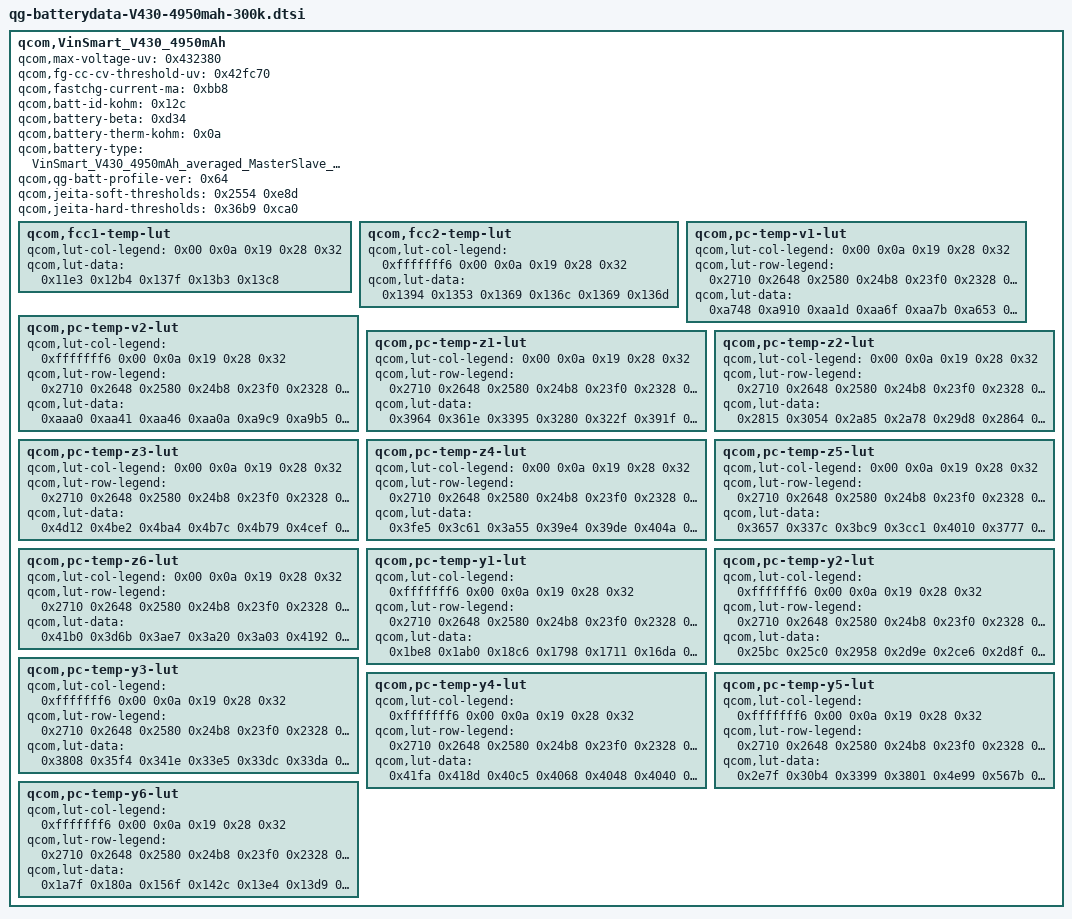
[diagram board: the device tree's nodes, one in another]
qcom,VinSmart_V430_4950mAh {
	qcom,max-voltage-uv = <0x432380>;
	qcom,fg-cc-cv-threshold-uv = <0x42fc70>;
	qcom,fastchg-current-ma = <0xbb8>;
	qcom,batt-id-kohm = <0x12c>;
	qcom,battery-beta = <0xd34>;
	qcom,battery-therm-kohm = <0x0a>;
	qcom,battery-type = "VinSmart_V430_4950mAh_averaged_MasterSlave_Nov11th2019";
	qcom,qg-batt-profile-ver = <0x64>;
	qcom,jeita-soft-thresholds = <0x2554 0xe8d>;
	qcom,jeita-hard-thresholds = <0x36b9 0xca0>;

	qcom,fcc1-temp-lut {
		qcom,lut-col-legend = <0x00 0x0a 0x19 0x28 0x32>;
		qcom,lut-data = <0x11e3 0x12b4 0x137f 0x13b3 0x13c8>;
	};

	qcom,fcc2-temp-lut {
		qcom,lut-col-legend = <0xfffffff6 0x00 0x0a 0x19 0x28 0x32>;
		qcom,lut-data = <0x1394 0x1353 0x1369 0x136c 0x1369 0x136d>;
	};

	qcom,pc-temp-v1-lut {
		qcom,lut-col-legend = <0x00 0x0a 0x19 0x28 0x32>;
		qcom,lut-row-legend = <0x2710 0x2648 0x2580 0x24b8 0x23f0 0x2328 0x2260 0x2198 0x20d0 0x2008 0x1f40 0x1e78 0x1db0 0x1ce8 0x1c20 0x1b58 0x1a90 0x19c8 0x1900 0x1838 0x1770 0x16a8 0x15e0 0x1518 0x1450 0x1388 0x12c0 0x11f8 0x1130 0x1068 0xfa0 0xed8 0xe10 0xd48 0xc80 0xbb8 0xaf0 0xa28 0x960 0x898 0x7d0 0x708 0x640 0x578 0x4b0 0x3e8 0x384 0x320 0x2bc 0x258 0x1f4 0x190 0x12c 0xc8 0x64 0x00>;
		qcom,lut-data = <0xa748 0xa910 0xaa1d 0xaa6f 0xaa7b 0xa653 0xa7fa 0xa968 0xa99a 0xa9a7 0xa56d 0xa70d 0xa86e 0xa8b7 0xa8cc 0xa492 0xa632 0xa771 0xa7ce 0xa7ea 0xa3bf 0xa556 0xa67f 0xa6e7 0xa707 0xa2f0 0xa47b 0xa590 0xa600 0xa621 0xa229 0xa3a6 0xa4b7 0xa51b 0xa53c 0xa171 0xa2d3 0xa3f3 0xa438 0xa459 0xa0d5 0xa206 0xa32c 0xa358 0xa379 0xa038 0xa149 0xa252 0xa27c 0xa29c 0x9f6a 0xa0a9 0xa178 0xa1a3 0xa1c0 0x9e50 0xa000 0xa0b3 0xa0cf 0xa0e9 0x9d45 0x9f1e 0xa001 0x9fff 0xa019 0x9c83 0x9e0a 0x9f42 0x9f36 0x9f50 0x9be3 0x9d20 0x9e5b 0x9e71 0x9e8b 0x9b5a 0x9c75 0x9d77 0x9db2 0x9dcc 0x9ae4 0x9be2 0x9cc1 0x9cff 0x9d15 0x9a78 0x9b59 0x9c26 0x9c59 0x9c6b 0x9a09 0x9adb 0x9b8e 0x9bb5 0x9bc5 0x9997 0x9a5d 0x9afc 0x9b12 0x9b1e 0x9927 0x99d8 0x9a5f 0x9a6c 0x9a76 0x98bf 0x9953 0x9993 0x99a4 0x99b8 0x9859 0x98d4 0x989f 0x98a1 0x98ca 0x97fb 0x9857 0x97db 0x97ce 0x97f8 0x97a4 0x97db 0x9744 0x9759 0x9776 0x9753 0x975c 0x96ce 0x9700 0x9712 0x9707 0x96df 0x967b 0x96a5 0x96ac 0x96c1 0x9678 0x963b 0x964b 0x9645 0x9680 0x9623 0x95fe 0x95f6 0x95e7 0x9644 0x95dc 0x95c2 0x95a5 0x9594 0x960e 0x95a6 0x958a 0x955a 0x954b 0x95db 0x9579 0x9556 0x951b 0x9507 0x95ab 0x9553 0x9526 0x94e6 0x94ca 0x957d 0x9531 0x94fa 0x94b1 0x948e 0x9551 0x9513 0x94d3 0x947d 0x9454 0x9528 0x94f1 0x94ab 0x944a 0x941b 0x94fd 0x94cd 0x9480 0x9417 0x93e0 0x94c9 0x94a2 0x9450 0x93e4 0x93a5 0x948a 0x9462 0x940e 0x93a2 0x935e 0x9440 0x940e 0x93b0 0x9345 0x9302 0x93e3 0x93ac 0x9342 0x92d8 0x9298 0x9371 0x9332 0x92ce 0x9266 0x9223 0x92f0 0x92a8 0x924b 0x91e5 0x91a0 0x9260 0x9206 0x91ad 0x914c 0x9109 0x91d3 0x9196 0x9124 0x90c7 0x9088 0x9176 0x913d 0x90d2 0x9074 0x9037 0x9151 0x911e 0x90b8 0x905f 0x9020 0x9133 0x9102 0x90a9 0x904c 0x900e 0x9111 0x90e4 0x9093 0x9036 0x8ffa 0x90bf 0x90a7 0x9058 0x8ff3 0x8fae 0x8fd0 0x8fb6 0x8f53 0x8ee0 0x8e8f 0x8e1d 0x8e02 0x8da9 0x8d31 0x8cde 0x8bf4 0x8bd2 0x8b7e 0x8aff 0x8aac 0x8910 0x88e6 0x8884 0x8804 0x87b2 0x8463 0x845a 0x83ef 0x836a 0x8327 0x7530 0x7530 0x7530 0x7530 0x7530>;
	};

	qcom,pc-temp-v2-lut {
		qcom,lut-col-legend = <0xfffffff6 0x00 0x0a 0x19 0x28 0x32>;
		qcom,lut-row-legend = <0x2710 0x2648 0x2580 0x24b8 0x23f0 0x2328 0x2260 0x2198 0x20d0 0x2008 0x1f40 0x1e78 0x1db0 0x1ce8 0x1c20 0x1b58 0x1a90 0x19c8 0x1900 0x1838 0x1770 0x16a8 0x15e0 0x1518 0x1450 0x1388 0x12c0 0x11f8 0x1130 0x1068 0xfa0 0xed8 0xe10 0xd48 0xc80 0xbb8 0xaf0 0xa28 0x960 0x898 0x7d0 0x708 0x640 0x578 0x4b0 0x3e8 0x384 0x320 0x2bc 0x258 0x1f4 0x190 0x12c 0xc8 0x64 0x00>;
		qcom,lut-data = <0xaaa0 0xaa41 0xaa46 0xaa0a 0xa9c9 0xa9b5 0xa921 0xa8d2 0xa8fd 0xa8e0 0xa8bc 0xa8b5 0xa7c2 0xa781 0xa7d0 0xa7cb 0xa7bb 0xa7be 0xa688 0xa655 0xa6c1 0xa6cc 0xa6c7 0xa6d0 0xa56d 0xa547 0xa5d0 0xa5e5 0xa5e3 0xa5ec 0xa465 0xa44a 0xa4e6 0xa503 0xa502 0xa50b 0xa36a 0xa357 0xa3fb 0xa41f 0xa41f 0xa429 0xa27f 0xa271 0xa315 0xa340 0xa341 0xa34a 0xa19f 0xa198 0xa230 0xa263 0xa265 0xa26e 0xa0c9 0xa0c7 0xa14b 0xa18a 0xa18c 0xa195 0xa006 0xa00f 0xa07d 0xa0b7 0xa0b8 0xa0c0 0x9f6d 0x9f86 0x9fdb 0x9ff3 0x9fe9 0x9ff0 0x9ecb 0x9f03 0x9f41 0x9f33 0x9f1f 0x9f24 0x9db5 0x9e22 0x9e6d 0x9e63 0x9e5c 0x9e61 0x9c13 0x9c99 0x9d4f 0x9d82 0x9d9e 0x9da5 0x9ad6 0x9b43 0x9c50 0x9cb9 0x9ce6 0x9cee 0x9a1a 0x9a80 0x9b9d 0x9c1d 0x9c3b 0x9c41 0x997c 0x99e3 0x9afd 0x9b8e 0x9b93 0x9b96 0x98d8 0x993c 0x9a46 0x9ae4 0x9ae9 0x9aec 0x9838 0x9890 0x997f 0x9a24 0x9a3b 0x9a41 0x97a2 0x97ed 0x98be 0x995b 0x9981 0x9989 0x9712 0x9751 0x9806 0x987f 0x98a0 0x98aa 0x9690 0x96c0 0x975b 0x97ad 0x97c3 0x97cf 0x9620 0x9642 0x96c5 0x9711 0x9724 0x972f 0x95bb 0x95d2 0x9640 0x9695 0x96a9 0x96b2 0x9563 0x9572 0x95ca 0x9625 0x963b 0x9643 0x9513 0x9523 0x9562 0x95bf 0x95d6 0x95dc 0x94cb 0x94df 0x9506 0x9561 0x957b 0x957e 0x9486 0x94a1 0x94bc 0x950c 0x9526 0x9527 0x9445 0x9469 0x947d 0x94bf 0x94d9 0x94d8 0x9407 0x9436 0x9446 0x9478 0x9492 0x9490 0x93ca 0x9405 0x9413 0x9435 0x9451 0x944f 0x9391 0x93d6 0x93e4 0x93f6 0x9413 0x9410 0x9359 0x93a5 0x93b6 0x93bb 0x93cf 0x93c9 0x9322 0x9375 0x938b 0x9386 0x9387 0x937a 0x92eb 0x9342 0x935e 0x934e 0x9338 0x9320 0x92b2 0x930b 0x932d 0x9312 0x92dd 0x92b7 0x9279 0x92d0 0x92f6 0x92d3 0x9280 0x924c 0x923d 0x928b 0x92b5 0x928e 0x922e 0x91f4 0x9201 0x923c 0x9268 0x9246 0x91e4 0x91a7 0x91c2 0x91e5 0x9212 0x91f5 0x9193 0x9155 0x9181 0x9186 0x91ad 0x9195 0x9134 0x90f8 0x9134 0x9125 0x913c 0x9124 0x90c8 0x908e 0x90db 0x90cc 0x90c0 0x90a3 0x904e 0x9013 0x907e 0x9079 0x904a 0x902a 0x8feb 0x8fb4 0x9006 0x9026 0x8ff8 0x8ff1 0x8fbf 0x8f8c 0x8fbd 0x8ff6 0x8fdc 0x8fdb 0x8fb2 0x8f81 0x8f5c 0x8fc0 0x8fbc 0x8fc6 0x8f9e 0x8f70 0x8eee 0x8f79 0x8f8a 0x8fa0 0x8f7e 0x8f4f 0x8e4f 0x8f0a 0x8f34 0x8f59 0x8f21 0x8ee9 0x8d54 0x8e2f 0x8e6b 0x8e65 0x8de7 0x8d9f 0x8beb 0x8cad 0x8cd5 0x8ca5 0x8c13 0x8bcb 0x89cf 0x8a72 0x8a97 0x8a4c 0x89ac 0x8967 0x86a1 0x873f 0x8776 0x8727 0x8669 0x8624 0x8141 0x8230 0x8296 0x825f 0x8187 0x8146 0x7397 0x75a4 0x7559 0x7359 0x7341 0x7466>;
	};

	qcom,pc-temp-z1-lut {
		qcom,lut-col-legend = <0x00 0x0a 0x19 0x28 0x32>;
		qcom,lut-row-legend = <0x2710 0x2648 0x2580 0x24b8 0x23f0 0x2328 0x2260 0x2198 0x20d0 0x2008 0x1f40 0x1e78 0x1db0 0x1ce8 0x1c20 0x1b58 0x1a90 0x19c8 0x1900 0x1838 0x1770 0x16a8 0x15e0 0x1518 0x1450 0x1388 0x12c0 0x11f8 0x1130 0x1068 0xfa0 0xed8 0xe10 0xd48 0xc80 0xbb8 0xaf0 0xa28 0x960 0x898 0x7d0 0x708 0x640 0x578 0x4b0 0x3e8 0x384 0x320 0x2bc 0x258 0x1f4 0x190 0x12c 0xc8 0x64 0x00>;
		qcom,lut-data = <0x3964 0x361e 0x3395 0x3280 0x322f 0x391f 0x3605 0x337d 0x3272 0x322a 0x3913 0x3605 0x337d 0x3269 0x3220 0x3923 0x3607 0x337b 0x3263 0x3218 0x392f 0x3604 0x336e 0x325d 0x3215 0x392a 0x35f8 0x3362 0x3257 0x3215 0x3916 0x35ef 0x3363 0x3255 0x3214 0x3904 0x35ea 0x3369 0x3255 0x3217 0x38f6 0x35e4 0x336b 0x3255 0x321b 0x38e6 0x35e3 0x336a 0x3257 0x3220 0x38d4 0x35eb 0x3369 0x325b 0x3226 0x38b9 0x35f2 0x3369 0x325e 0x3229 0x38a0 0x35e9 0x3368 0x325f 0x322a 0x388d 0x35d1 0x3367 0x3260 0x322b 0x387d 0x35c6 0x3362 0x3260 0x322c 0x3876 0x35cc 0x335e 0x3260 0x322e 0x3879 0x35d7 0x335f 0x3262 0x3230 0x387d 0x35de 0x3365 0x3263 0x3232 0x387a 0x35e5 0x336b 0x3265 0x3233 0x386e 0x35ec 0x3375 0x3267 0x3235 0x3864 0x35f5 0x337c 0x326b 0x3238 0x3865 0x35ff 0x337c 0x326e 0x323a 0x386b 0x3606 0x337a 0x3271 0x323d 0x386d 0x360e 0x337a 0x3275 0x3240 0x386f 0x3613 0x337d 0x3279 0x3244 0x3872 0x3614 0x3382 0x327c 0x3249 0x3870 0x3614 0x338a 0x3280 0x324d 0x385e 0x3616 0x3394 0x3286 0x3250 0x384b 0x361f 0x3398 0x328b 0x3254 0x384e 0x3626 0x3398 0x328e 0x3258 0x3864 0x3628 0x3399 0x3292 0x325e 0x3873 0x3629 0x339f 0x3297 0x3262 0x386e 0x362b 0x33a8 0x329d 0x3267 0x3862 0x3630 0x33ad 0x32a3 0x326b 0x3863 0x3638 0x33ae 0x32a7 0x3270 0x387f 0x3640 0x33b0 0x32aa 0x3274 0x389f 0x364c 0x33b3 0x32af 0x3277 0x38a9 0x3657 0x33b8 0x32b6 0x327c 0x38ad 0x3663 0x33bf 0x32bb 0x3280 0x38b0 0x3671 0x33cd 0x32c0 0x3285 0x38b7 0x3675 0x33d8 0x32c5 0x328a 0x38bf 0x3677 0x33da 0x32c8 0x328e 0x38b6 0x3679 0x33dc 0x32cb 0x3292 0x389c 0x366f 0x33de 0x32d2 0x3298 0x3896 0x367b 0x33dd 0x32d9 0x329c 0x38a7 0x3674 0x33e3 0x32da 0x329d 0x38ab 0x3669 0x33e4 0x32dd 0x32a0 0x38af 0x366b 0x33e3 0x32dd 0x32a1 0x38b1 0x367a 0x33e3 0x32e5 0x32a5 0x38a0 0x367a 0x33e3 0x32e5 0x32a9 0x38ab 0x36a3 0x33f4 0x32ec 0x32af 0x38c5 0x369a 0x33fa 0x32f9 0x32b9 0x38c2 0x36b3 0x3409 0x3305 0x32c5 0x38e8 0x36cb 0x3427 0x331e 0x32d6 0x38e8 0x36cb 0x3427 0x331e 0x32d6 0x38e8 0x36cb 0x3427 0x331e 0x32d6>;
	};

	qcom,pc-temp-z2-lut {
		qcom,lut-col-legend = <0x00 0x0a 0x19 0x28 0x32>;
		qcom,lut-row-legend = <0x2710 0x2648 0x2580 0x24b8 0x23f0 0x2328 0x2260 0x2198 0x20d0 0x2008 0x1f40 0x1e78 0x1db0 0x1ce8 0x1c20 0x1b58 0x1a90 0x19c8 0x1900 0x1838 0x1770 0x16a8 0x15e0 0x1518 0x1450 0x1388 0x12c0 0x11f8 0x1130 0x1068 0xfa0 0xed8 0xe10 0xd48 0xc80 0xbb8 0xaf0 0xa28 0x960 0x898 0x7d0 0x708 0x640 0x578 0x4b0 0x3e8 0x384 0x320 0x2bc 0x258 0x1f4 0x190 0x12c 0xc8 0x64 0x00>;
		qcom,lut-data = <0x2815 0x3054 0x2a85 0x2a78 0x29d8 0x2864 0x296f 0x514d 0x2a4b 0x29ce 0x2865 0x2962 0x3c2a 0x2a8d 0x29f7 0x284d 0x2953 0x31d8 0x2ac6 0x2a39 0x283b 0x2948 0x2f08 0x2aca 0x2a4d 0x283a 0x2940 0x2d04 0x2ac1 0x2a7e 0x283d 0x293b 0x2c62 0x2ab4 0x2aab 0x283d 0x293c 0x2c6a 0x2a96 0x2a8d 0x2836 0x293f 0x2c85 0x2a74 0x2a4e 0x282d 0x2943 0x2c9a 0x2a60 0x2a3a 0x2828 0x2955 0x2cad 0x2a50 0x2a44 0x2824 0x2968 0x2c8d 0x2a42 0x2a45 0x281e 0x2956 0x2c49 0x2a30 0x29ec 0x2813 0x2917 0x2c33 0x2a22 0x2979 0x2800 0x28f5 0x2cf2 0x2a2b 0x296f 0x27ec 0x28fb 0x2dd2 0x2a44 0x2990 0x27d7 0x2906 0x2d44 0x2a45 0x29ab 0x27c3 0x2912 0x2b4f 0x2a13 0x29b7 0x27b2 0x2923 0x2a6f 0x29ec 0x29c2 0x27a5 0x292d 0x2a7b 0x2a17 0x29cf 0x2799 0x292d 0x2a88 0x2a68 0x29de 0x278a 0x292b 0x2a82 0x2a7c 0x29e5 0x2776 0x292e 0x2a68 0x2a7a 0x29e7 0x2766 0x2934 0x2a58 0x2a76 0x29e9 0x275b 0x293d 0x2a57 0x2a41 0x29f9 0x2753 0x294f 0x2a5f 0x29ef 0x2a1a 0x274b 0x296d 0x2a6f 0x2a02 0x2a52 0x2709 0x2983 0x2a87 0x2aa5 0x2ac9 0x26b3 0x2990 0x2a9a 0x2b07 0x2b0f 0x2672 0x299b 0x2aaf 0x2aef 0x2aad 0x2600 0x29a8 0x2abc 0x2abc 0x2a00 0x25b1 0x29b7 0x2abe 0x2a83 0x29b3 0x25a6 0x29c4 0x2abf 0x2a3b 0x2988 0x25a2 0x29cd 0x2abf 0x2a1e 0x297c 0x2592 0x29d6 0x2abe 0x2a4b 0x2992 0x254a 0x29e6 0x2abd 0x2a92 0x29b1 0x24fd 0x2a03 0x2ac3 0x2abd 0x29ce 0x24e9 0x2a1d 0x2ad1 0x2ae0 0x29f9 0x24da 0x2a2c 0x2ae7 0x2b06 0x2a20 0x24d1 0x2a36 0x2b13 0x2b3c 0x2a41 0x24de 0x2a3e 0x2b31 0x2b64 0x2a5a 0x24fb 0x2a44 0x2b2c 0x2b77 0x2a68 0x2535 0x2a4d 0x2b24 0x2b84 0x2a75 0x257a 0x2a60 0x2b2b 0x2b6d 0x2a91 0x258c 0x2915 0x2b51 0x2b3b 0x2a9b 0x25ed 0x2ae7 0x2b65 0x2adb 0x2a88 0x25e8 0x2e5c 0x2b62 0x2adb 0x2a86 0x25b6 0x30da 0x2ba6 0x2ad9 0x2a67 0x25cb 0x397d 0x2bc7 0x2af4 0x2ae6 0x25ce 0x4dff 0x2beb 0x2b68 0x2b80 0x25b5 0x366e 0x2be2 0x2b55 0x2a5a 0x257c 0x3273 0x2ba1 0x2ab4 0x29b2 0x2516 0x29b4 0x2bb2 0x2a71 0x2988 0x24d0 0x2771 0x2b69 0x2a3a 0x294a 0x24d0 0x2771 0x2b69 0x2a3a 0x294a 0x24d0 0x2771 0x2b69 0x2a3a 0x294a>;
	};

	qcom,pc-temp-z3-lut {
		qcom,lut-col-legend = <0x00 0x0a 0x19 0x28 0x32>;
		qcom,lut-row-legend = <0x2710 0x2648 0x2580 0x24b8 0x23f0 0x2328 0x2260 0x2198 0x20d0 0x2008 0x1f40 0x1e78 0x1db0 0x1ce8 0x1c20 0x1b58 0x1a90 0x19c8 0x1900 0x1838 0x1770 0x16a8 0x15e0 0x1518 0x1450 0x1388 0x12c0 0x11f8 0x1130 0x1068 0xfa0 0xed8 0xe10 0xd48 0xc80 0xbb8 0xaf0 0xa28 0x960 0x898 0x7d0 0x708 0x640 0x578 0x4b0 0x3e8 0x384 0x320 0x2bc 0x258 0x1f4 0x190 0x12c 0xc8 0x64 0x00>;
		qcom,lut-data = <0x4d12 0x4be2 0x4ba4 0x4b7c 0x4b79 0x4cef 0x4c85 0x4b72 0x4b95 0x4b88 0x4ce3 0x4c94 0x4ba9 0x4ba2 0x4b92 0x4cdd 0x4c99 0x4bd5 0x4bad 0x4b98 0x4cdc 0x4c98 0x4be8 0x4bb4 0x4b9e 0x4cdf 0x4c92 0x4bf6 0x4bb9 0x4ba4 0x4ce7 0x4c8c 0x4c03 0x4bbb 0x4ba9 0x4cee 0x4c88 0x4c12 0x4bbb 0x4ba9 0x4cf4 0x4c85 0x4c19 0x4bba 0x4ba9 0x4cfa 0x4c80 0x4c14 0x4bb9 0x4ba9 0x4cff 0x4c7b 0x4c0b 0x4bb4 0x4ba7 0x4d05 0x4c7a 0x4c02 0x4bb0 0x4ba4 0x4d08 0x4c7a 0x4bf9 0x4bac 0x4b9e 0x4d02 0x4c78 0x4bf4 0x4ba9 0x4b97 0x4cf1 0x4c72 0x4bf3 0x4ba7 0x4b94 0x4ce0 0x4c5f 0x4bf1 0x4ba6 0x4b93 0x4cd3 0x4c44 0x4be9 0x4ba2 0x4b91 0x4cc5 0x4c31 0x4bd6 0x4b9b 0x4b8c 0x4cb6 0x4c21 0x4bcd 0x4b96 0x4b88 0x4ca6 0x4c1a 0x4bcc 0x4b97 0x4b88 0x4c95 0x4c20 0x4bcb 0x4b9a 0x4b88 0x4c86 0x4c28 0x4bcf 0x4b9c 0x4b87 0x4c76 0x4c2a 0x4bdb 0x4b9c 0x4b85 0x4c66 0x4c32 0x4be0 0x4b9d 0x4b83 0x4c53 0x4c3c 0x4bdd 0x4b97 0x4b7f 0x4c3f 0x4c45 0x4bda 0x4b8d 0x4b7b 0x4c2c 0x4c51 0x4bd7 0x4b8d 0x4b7f 0x4c1a 0x4c55 0x4bd4 0x4b94 0x4b9d 0x4c08 0x4c52 0x4bd3 0x4b9e 0x4bb2 0x4bf6 0x4c4e 0x4bd4 0x4bab 0x4baf 0x4be3 0x4c49 0x4bd5 0x4bb6 0x4ba8 0x4bd2 0x4c41 0x4bd6 0x4bb6 0x4ba3 0x4bc6 0x4c39 0x4bd8 0x4baf 0x4b9d 0x4bbb 0x4c30 0x4bd9 0x4ba9 0x4b98 0x4baf 0x4c26 0x4bd6 0x4ba6 0x4b93 0x4b9a 0x4c1d 0x4bd4 0x4ba2 0x4b8e 0x4b84 0x4c14 0x4bd1 0x4b9e 0x4b8a 0x4b76 0x4c0f 0x4bcf 0x4b9a 0x4b87 0x4b5e 0x4c0f 0x4bcd 0x4b98 0x4b85 0x4b4c 0x4c0e 0x4bcc 0x4b97 0x4b84 0x4b4a 0x4c0d 0x4bcb 0x4b97 0x4b83 0x4b49 0x4c08 0x4bc8 0x4b95 0x4b84 0x4b46 0x4c05 0x4bc5 0x4b94 0x4b86 0x4b44 0x4c08 0x4bc4 0x4b94 0x4b88 0x4b43 0x4b6f 0x4bbe 0x4b90 0x4b86 0x4b41 0x4b3c 0x4bb2 0x4b89 0x4b80 0x4b41 0x4b3b 0x4bad 0x4b82 0x4b7c 0x4b42 0x4b3a 0x4b8b 0x4b81 0x4b77 0x4b41 0x4b39 0x4b85 0x4b7f 0x4b6d 0x4b41 0x4b38 0x4b83 0x4b78 0x4b67 0x4b42 0x4b39 0x4b9a 0x4b7e 0x4b80 0x4b43 0x4b3a 0x4b99 0x4b85 0x4b88 0x4b45 0x4b3c 0x4b74 0x4b85 0x4b89 0x4b47 0x4b3f 0x4b75 0x4b83 0x4b87 0x4b47 0x4b3f 0x4b75 0x4b83 0x4b87 0x4b47 0x4b3f 0x4b75 0x4b83 0x4b87>;
	};

	qcom,pc-temp-z4-lut {
		qcom,lut-col-legend = <0x00 0x0a 0x19 0x28 0x32>;
		qcom,lut-row-legend = <0x2710 0x2648 0x2580 0x24b8 0x23f0 0x2328 0x2260 0x2198 0x20d0 0x2008 0x1f40 0x1e78 0x1db0 0x1ce8 0x1c20 0x1b58 0x1a90 0x19c8 0x1900 0x1838 0x1770 0x16a8 0x15e0 0x1518 0x1450 0x1388 0x12c0 0x11f8 0x1130 0x1068 0xfa0 0xed8 0xe10 0xd48 0xc80 0xbb8 0xaf0 0xa28 0x960 0x898 0x7d0 0x708 0x640 0x578 0x4b0 0x3e8 0x384 0x320 0x2bc 0x258 0x1f4 0x190 0x12c 0xc8 0x64 0x00>;
		qcom,lut-data = <0x3fe5 0x3c61 0x3a55 0x39e4 0x39de 0x404a 0x3cd2 0x3adc 0x3a26 0x39eb 0x4017 0x3c78 0x3aa0 0x3a21 0x39f9 0x3f55 0x3bdf 0x3a61 0x3a08 0x39ea 0x3e85 0x3b76 0x3a32 0x39f0 0x39da 0x3df4 0x3b2b 0x3a09 0x39d6 0x39c6 0x3d74 0x3aec 0x39df 0x39c0 0x39b3 0x3d01 0x3ab7 0x39ac 0x39ac 0x39a3 0x3c94 0x3a8b 0x3989 0x399b 0x3995 0x3c35 0x3a61 0x397c 0x398c 0x3986 0x3bf4 0x3a2f 0x3973 0x397e 0x3978 0x3bc7 0x3a04 0x3966 0x3973 0x396e 0x3b9e 0x39f5 0x3955 0x396b 0x396a 0x3b70 0x39eb 0x394c 0x3964 0x3966 0x3b40 0x39e2 0x394b 0x395c 0x3961 0x3b18 0x39d8 0x394b 0x3956 0x395a 0x3af8 0x39ce 0x394f 0x3951 0x3953 0x3adf 0x39c9 0x3955 0x394b 0x394c 0x3ad4 0x39c6 0x3957 0x3948 0x3947 0x3ace 0x39c1 0x3953 0x3948 0x3948 0x3acb 0x39b3 0x3950 0x394a 0x394e 0x3acb 0x39a1 0x3967 0x3959 0x395c 0x3acc 0x3998 0x39a8 0x39ad 0x39a3 0x3acd 0x398f 0x39d1 0x39e7 0x39dc 0x3acf 0x3988 0x39e4 0x39e4 0x39da 0x3ad3 0x398a 0x39ed 0x39da 0x39cf 0x3ad8 0x3990 0x39e6 0x39cc 0x39bc 0x3adf 0x3995 0x39ce 0x39b3 0x3990 0x3ae6 0x3997 0x39b8 0x3999 0x396d 0x3aec 0x3999 0x39a6 0x397f 0x3962 0x3af3 0x3997 0x3995 0x396a 0x395b 0x3af7 0x3991 0x3986 0x395e 0x3955 0x3af6 0x398b 0x3979 0x3957 0x394e 0x3af3 0x3987 0x396e 0x3954 0x394b 0x3af1 0x3983 0x3966 0x3953 0x394c 0x3af3 0x3980 0x3960 0x3953 0x394d 0x3af4 0x397e 0x395e 0x3953 0x394e 0x3af3 0x397c 0x395d 0x3953 0x3951 0x3af0 0x3978 0x395d 0x3954 0x3954 0x3aeb 0x3975 0x3965 0x395d 0x395c 0x3ae4 0x3974 0x396b 0x3965 0x3962 0x3ad9 0x3978 0x3967 0x3962 0x3960 0x3acc 0x3979 0x3962 0x395c 0x395a 0x3ab7 0x396f 0x3962 0x395f 0x395c 0x3a6a 0x39e9 0x395a 0x395c 0x395a 0x3a60 0x3a0d 0x3947 0x394a 0x3948 0x3a5e 0x3a05 0x3942 0x3944 0x3941 0x3a59 0x3a00 0x3959 0x3936 0x3934 0x3a53 0x39fb 0x3956 0x3929 0x392b 0x3a4f 0x39f8 0x3955 0x3931 0x3932 0x3a54 0x3a02 0x3951 0x3948 0x393a 0x3a6f 0x3a13 0x395b 0x3948 0x393b 0x3a84 0x3a20 0x3987 0x394b 0x393e 0x3a9d 0x3a2f 0x398c 0x3951 0x3943 0x3a9d 0x3a2f 0x398c 0x3951 0x3943 0x3a9d 0x3a2f 0x398c 0x3951 0x3943>;
	};

	qcom,pc-temp-z5-lut {
		qcom,lut-col-legend = <0x00 0x0a 0x19 0x28 0x32>;
		qcom,lut-row-legend = <0x2710 0x2648 0x2580 0x24b8 0x23f0 0x2328 0x2260 0x2198 0x20d0 0x2008 0x1f40 0x1e78 0x1db0 0x1ce8 0x1c20 0x1b58 0x1a90 0x19c8 0x1900 0x1838 0x1770 0x16a8 0x15e0 0x1518 0x1450 0x1388 0x12c0 0x11f8 0x1130 0x1068 0xfa0 0xed8 0xe10 0xd48 0xc80 0xbb8 0xaf0 0xa28 0x960 0x898 0x7d0 0x708 0x640 0x578 0x4b0 0x3e8 0x384 0x320 0x2bc 0x258 0x1f4 0x190 0x12c 0xc8 0x64 0x00>;
		qcom,lut-data = <0x3657 0x337c 0x3bc9 0x3cc1 0x4010 0x3777 0x3ced 0x3314 0x42c7 0x45d7 0x392a 0x3e89 0x3838 0x463e 0x483f 0x3b91 0x3f53 0x3e0f 0x4a87 0x4ae6 0x3e03 0x3ffd 0x438d 0x4de8 0x4dea 0x4044 0x4082 0x49b1 0x50ce 0x51b5 0x427a 0x412c 0x4fea 0x5342 0x557e 0x449d 0x42a0 0x55f1 0x55c6 0x5801 0x46b7 0x4474 0x5ad5 0x5843 0x5a33 0x48d7 0x45b3 0x5eca 0x5a33 0x5da3 0x4b1f 0x46e7 0x62a3 0x5c1c 0x6315 0x4dbd 0x4882 0x671f 0x5d43 0x65c6 0x4f48 0x4c28 0x6c6a 0x5f76 0x637a 0x4f43 0x5222 0x71c4 0x6332 0x6066 0x4ee4 0x54c6 0x784b 0x68ae 0x6208 0x4e53 0x5157 0x7cc0 0x6f3a 0x69f2 0x4d14 0x4b9b 0x79b3 0x709a 0x6ec2 0x4b2d 0x487a 0x70af 0x6d24 0x6f69 0x4914 0x4600 0x6d2d 0x6a91 0x702b 0x467c 0x44fb 0x7182 0x75b5 0x7582 0x43d9 0x4954 0x7a51 0x8ada 0x8047 0x41ad 0x5109 0x9557 0x8fab 0x828e 0x3fb8 0x576b 0xc7be 0x89bd 0x7423 0x3dd4 0x6326 0xd861 0x8025 0x61a6 0x3bed 0x72c2 0xbdaf 0x6ab6 0x5284 0x3a1c 0x8c69 0x9c63 0x51c6 0x454c 0x387d 0xada7 0x88d0 0x4cbf 0x4526 0x3705 0xb840 0x794a 0x4d54 0x58cb 0x35a2 0xb598 0x73d6 0x4f84 0x69bd 0x3444 0xb0b0 0x72a8 0x5eb4 0x6db9 0x32e7 0xa8e5 0x7225 0x7389 0x7045 0x31c5 0x9bf0 0x760e 0x7b74 0x7445 0x30f8 0x8f97 0x813e 0x7f55 0x7b0e 0x304a 0x82b1 0x8a74 0x8449 0x8037 0x2f91 0x75a4 0x923e 0x8f16 0x8364 0x2e91 0x6dc5 0x9826 0x984b 0x859f 0x2db3 0x67f7 0x9b9d 0x9614 0x8490 0x2d53 0x652e 0x9e59 0x8da6 0x7f37 0x2cdd 0x6813 0x9e75 0x866f 0x786b 0x2c88 0x6dda 0x9b3e 0x7ecb 0x6d04 0x2c94 0x6f35 0x9638 0x76f8 0x640d 0x2cc1 0x69c2 0x8cad 0x708d 0x63b0 0x2ce1 0x6826 0x831f 0x6b67 0x6415 0x2d09 0x7395 0x8094 0x6841 0x64ef 0x2e61 0x3fde 0x80db 0x644d 0x635f 0x2e11 0x2f0d 0x7747 0x60e3 0x5d84 0x2de9 0x2ead 0x6e4f 0x583b 0x5859 0x2ded 0x2e85 0x467e 0x5e01 0x5b7f 0x2de9 0x2e7f 0x4377 0x66f8 0x5659 0x2df5 0x2e86 0x43ab 0x5724 0x4993 0x2e43 0x2ed4 0x5220 0x4ad8 0x5695 0x2e56 0x2e71 0x4a07 0x4b23 0x56da 0x2dce 0x2e64 0x37b4 0x481e 0x5255 0x2d4f 0x2db8 0x3677 0x42fb 0x49f2 0x2d4f 0x2db8 0x3677 0x42fb 0x49f2 0x2d4f 0x2db8 0x3677 0x42fb 0x49f2>;
	};

	qcom,pc-temp-z6-lut {
		qcom,lut-col-legend = <0x00 0x0a 0x19 0x28 0x32>;
		qcom,lut-row-legend = <0x2710 0x2648 0x2580 0x24b8 0x23f0 0x2328 0x2260 0x2198 0x20d0 0x2008 0x1f40 0x1e78 0x1db0 0x1ce8 0x1c20 0x1b58 0x1a90 0x19c8 0x1900 0x1838 0x1770 0x16a8 0x15e0 0x1518 0x1450 0x1388 0x12c0 0x11f8 0x1130 0x1068 0xfa0 0xed8 0xe10 0xd48 0xc80 0xbb8 0xaf0 0xa28 0x960 0x898 0x7d0 0x708 0x640 0x578 0x4b0 0x3e8 0x384 0x320 0x2bc 0x258 0x1f4 0x190 0x12c 0xc8 0x64 0x00>;
		qcom,lut-data = <0x41b0 0x3d6b 0x3ae7 0x3a20 0x3a03 0x4192 0x3dc5 0x3aff 0x3a45 0x3a0e 0x414d 0x3d8f 0x3af4 0x3a46 0x3a16 0x40cb 0x3d30 0x3ae8 0x3a3e 0x3a13 0x4052 0x3cea 0x3ad6 0x3a36 0x3a0f 0x3ffd 0x3cb2 0x3ac2 0x3a2c 0x3a0a 0x3fb4 0x3c83 0x3ab0 0x3a22 0x3a04 0x3f75 0x3c5d 0x3a9e 0x3a1a 0x39ff 0x3f3d 0x3c3d 0x3a8e 0x3a12 0x39f9 0x3f09 0x3c1f 0x3a83 0x3a0a 0x39f3 0x3ed9 0x3c02 0x3a79 0x3a02 0x39ed 0x3eac 0x3be7 0x3a6e 0x39fb 0x39e8 0x3e82 0x3bd4 0x3a60 0x39f5 0x39e2 0x3e58 0x3bc4 0x3a58 0x39f0 0x39dd 0x3e2f 0x3bb4 0x3a55 0x39ec 0x39d9 0x3e0f 0x3ba1 0x3a53 0x39e8 0x39d5 0x3df8 0x3b90 0x3a4e 0x39e4 0x39d2 0x3de5 0x3b89 0x3a48 0x39de 0x39cc 0x3dd5 0x3b86 0x3a45 0x39db 0x39c8 0x3dc8 0x3b84 0x3a45 0x39db 0x39c9 0x3dbd 0x3b83 0x3a45 0x39dd 0x39cb 0x3db3 0x3b82 0x3a52 0x39e7 0x39d2 0x3daa 0x3b83 0x3a75 0x3a0c 0x39ef 0x3da0 0x3b85 0x3a8a 0x3a25 0x3a08 0x3d95 0x3b8a 0x3a92 0x3a22 0x3a06 0x3d89 0x3b93 0x3a96 0x3a1a 0x3a00 0x3d80 0x3ba0 0x3a93 0x3a13 0x39fb 0x3d78 0x3ba6 0x3a88 0x3a0e 0x39f8 0x3d71 0x3ba7 0x3a80 0x3a0a 0x39f6 0x3d6c 0x3ba8 0x3a7a 0x3a07 0x39f1 0x3d66 0x3ba7 0x3a75 0x3a04 0x39eb 0x3d62 0x3ba3 0x3a72 0x3a00 0x39e6 0x3d61 0x3ba0 0x3a6f 0x39fa 0x39e1 0x3d61 0x3b9d 0x3a6d 0x39f6 0x39dd 0x3d61 0x3b9b 0x3a6a 0x39f5 0x39db 0x3d62 0x3b9a 0x3a68 0x39f4 0x39d9 0x3d63 0x3b9c 0x3a69 0x39f3 0x39d9 0x3d64 0x3b9d 0x3a6a 0x39f1 0x39d8 0x3d65 0x3b9f 0x3a6b 0x39f1 0x39d8 0x3d65 0x3ba1 0x3a72 0x39f6 0x39dc 0x3d66 0x3ba4 0x3a77 0x39fb 0x39df 0x3d67 0x3ba9 0x3a76 0x39fa 0x39df 0x3d66 0x3bad 0x3a75 0x39f8 0x39df 0x3d5f 0x3bb1 0x3a78 0x39fa 0x39e2 0x3d46 0x3ba0 0x3a76 0x39f8 0x39e1 0x3d3f 0x3b9b 0x3a6c 0x39ee 0x39d6 0x3d41 0x3b99 0x3a68 0x39e9 0x39d1 0x3d41 0x3b99 0x3a60 0x39e3 0x39ca 0x3d42 0x3b99 0x3a5e 0x39dd 0x39c1 0x3d45 0x3b9e 0x3a60 0x39de 0x39c2 0x3d51 0x3bac 0x3a6f 0x39ed 0x39d4 0x3d66 0x3bba 0x3a79 0x39f3 0x39db 0x3d7d 0x3bcd 0x3a7f 0x39f9 0x39df 0x3d9f 0x3be9 0x3a8c 0x39ff 0x39e5 0x3d9f 0x3be9 0x3a8c 0x39ff 0x39e5 0x3d9f 0x3be9 0x3a8c 0x39ff 0x39e5>;
	};

	qcom,pc-temp-y1-lut {
		qcom,lut-col-legend = <0xfffffff6 0x00 0x0a 0x19 0x28 0x32>;
		qcom,lut-row-legend = <0x2710 0x2648 0x2580 0x24b8 0x23f0 0x2328 0x2260 0x2198 0x20d0 0x2008 0x1f40 0x1e78 0x1db0 0x1ce8 0x1c20 0x1b58 0x1a90 0x19c8 0x1900 0x1838 0x1770 0x16a8 0x15e0 0x1518 0x1450 0x1388 0x12c0 0x11f8 0x1130 0x1068 0xfa0 0xed8 0xe10 0xd48 0xc80 0xbb8 0xaf0 0xa28 0x960 0x898 0x7d0 0x708 0x640 0x578 0x4b0 0x3e8 0x384 0x320 0x2bc 0x258 0x1f4 0x190 0x12c 0xc8 0x64 0x00>;
		qcom,lut-data = <0x1be8 0x1ab0 0x18c6 0x1798 0x1711 0x16da 0x1bec 0x1a8f 0x18d6 0x179e 0x170d 0x16d8 0x1bef 0x1a79 0x18e3 0x17a2 0x170a 0x16d5 0x1bf0 0x1a6c 0x18ed 0x17a4 0x1706 0x16d1 0x1bf1 0x1a66 0x18f3 0x17a4 0x1704 0x16ce 0x1bf1 0x1a64 0x18f5 0x17a4 0x1701 0x16cd 0x1bf0 0x1a6c 0x18f1 0x17a2 0x16ff 0x16cb 0x1bee 0x1a79 0x18ea 0x179f 0x16fe 0x16ca 0x1bf4 0x1a7a 0x18ea 0x179e 0x16fd 0x16c9 0x1c0b 0x1a6c 0x18ed 0x179f 0x16fb 0x16c7 0x1c16 0x1a62 0x18f1 0x17a0 0x16fa 0x16c6 0x1c16 0x1a68 0x18f6 0x179f 0x16f8 0x16c7 0x1c16 0x1a74 0x18fc 0x179e 0x16f6 0x16c8 0x1c10 0x1a79 0x18fd 0x17a0 0x16f7 0x16c8 0x1bfd 0x1a7a 0x18fa 0x17a4 0x16f9 0x16c8 0x1bf5 0x1a7a 0x18f7 0x17a7 0x16fa 0x16c7 0x1bf7 0x1a7b 0x1903 0x17a8 0x16f9 0x16c8 0x1bfa 0x1a7c 0x1917 0x17a8 0x16f8 0x16c9 0x1bfc 0x1a7d 0x1918 0x17a8 0x16f8 0x16c9 0x1bfe 0x1a7e 0x1907 0x17a6 0x16f9 0x16cb 0x1c03 0x1a81 0x18fc 0x17a5 0x16fa 0x16cc 0x1c15 0x1a7e 0x18fd 0x17a9 0x16fc 0x16ce 0x1c26 0x1a79 0x18ff 0x17ad 0x16fe 0x16d0 0x1c29 0x1a79 0x1901 0x17ae 0x1700 0x16d2 0x1c2a 0x1a7f 0x1906 0x17ae 0x1703 0x16d4 0x1c29 0x1a83 0x190d 0x17ad 0x1706 0x16d6 0x1c17 0x1a7f 0x191a 0x17b2 0x1708 0x16d8 0x1c04 0x1a7b 0x1926 0x17b8 0x170b 0x16db 0x1bff 0x1a7b 0x1923 0x17b9 0x170d 0x16de 0x1bfc 0x1a7c 0x1914 0x17ba 0x1710 0x16e2 0x1bfd 0x1a7d 0x190c 0x17bc 0x1714 0x16e6 0x1c0e 0x1a81 0x1912 0x17c3 0x171a 0x16ea 0x1c1e 0x1a86 0x1919 0x17cc 0x1720 0x16ee 0x1c25 0x1a8a 0x1919 0x17cd 0x1723 0x16f0 0x1c2a 0x1a8c 0x1915 0x17cb 0x1726 0x16f3 0x1c28 0x1a8a 0x1913 0x17ca 0x1728 0x16f5 0x1c13 0x1a87 0x1916 0x17ce 0x172b 0x16f8 0x1c05 0x1a83 0x1918 0x17d2 0x172e 0x16fa 0x1c06 0x1a87 0x1918 0x17d3 0x172f 0x16fd 0x1c09 0x1a96 0x1917 0x17d6 0x1730 0x1700 0x1c0c 0x1a9f 0x1918 0x17da 0x1732 0x1703 0x1c0e 0x1a97 0x1923 0x17e4 0x1735 0x1705 0x1c11 0x1a8f 0x192c 0x17e9 0x1738 0x1708 0x1c16 0x1a96 0x192b 0x17de 0x173c 0x170e 0x1c1f 0x1aa3 0x1928 0x17e5 0x1743 0x1712 0x1c27 0x1aab 0x193e 0x17e5 0x174b 0x1715 0x1c2d 0x1ab3 0x1931 0x17f2 0x1747 0x1715 0x1c3b 0x1aba 0x194d 0x17ed 0x1748 0x1713 0x1c4e 0x1ac0 0x193f 0x17f6 0x1748 0x1715 0x1c68 0x1ad0 0x193e 0x17f2 0x1748 0x1716 0x1c87 0x1ad1 0x193b 0x17f0 0x174b 0x1719 0x1caf 0x1ada 0x195d 0x17fe 0x1754 0x1721 0x1cf1 0x1af5 0x1963 0x1807 0x1765 0x172a 0x1d51 0x1b2a 0x196f 0x1819 0x1774 0x1738 0x1d51 0x1b2a 0x196f 0x1819 0x1774 0x1738 0x1d51 0x1b2a 0x196f 0x1819 0x1774 0x1738>;
	};

	qcom,pc-temp-y2-lut {
		qcom,lut-col-legend = <0xfffffff6 0x00 0x0a 0x19 0x28 0x32>;
		qcom,lut-row-legend = <0x2710 0x2648 0x2580 0x24b8 0x23f0 0x2328 0x2260 0x2198 0x20d0 0x2008 0x1f40 0x1e78 0x1db0 0x1ce8 0x1c20 0x1b58 0x1a90 0x19c8 0x1900 0x1838 0x1770 0x16a8 0x15e0 0x1518 0x1450 0x1388 0x12c0 0x11f8 0x1130 0x1068 0xfa0 0xed8 0xe10 0xd48 0xc80 0xbb8 0xaf0 0xa28 0x960 0x898 0x7d0 0x708 0x640 0x578 0x4b0 0x3e8 0x384 0x320 0x2bc 0x258 0x1f4 0x190 0x12c 0xc8 0x64 0x00>;
		qcom,lut-data = <0x25bc 0x25c0 0x2958 0x2d9e 0x2ce6 0x2d8f 0x25bc 0x25c3 0x2988 0x2d7a 0x2d05 0x2d44 0x25bd 0x25c7 0x29b8 0x2d50 0x2cfe 0x2cf4 0x25bd 0x25cb 0x29e5 0x2d26 0x2ce2 0x2ca8 0x25bd 0x25d0 0x2a0c 0x2cfd 0x2cc4 0x2c66 0x25be 0x25d6 0x2a29 0x2cdc 0x2cb7 0x2c36 0x25be 0x25dd 0x2a3c 0x2cbc 0x2c9c 0x2c12 0x25be 0x25e4 0x2a4c 0x2c9f 0x2c72 0x2bf8 0x25bf 0x25e5 0x2a5b 0x2c8f 0x2c64 0x2bed 0x25bf 0x25e5 0x2a67 0x2c83 0x2c4d 0x2be8 0x25c0 0x25e6 0x2a7b 0x2c7e 0x2c43 0x2be5 0x25c1 0x2697 0x2ad2 0x2c7d 0x2c5b 0x2be9 0x25c2 0x2795 0x2b40 0x2c7e 0x2c84 0x2bf2 0x25c1 0x2781 0x2b5f 0x2c89 0x2ca6 0x2c02 0x25c1 0x2674 0x2b68 0x2cb4 0x2cc4 0x2c31 0x25c1 0x25d8 0x2b74 0x2ce4 0x2ce6 0x2c62 0x25c1 0x25d7 0x2b9c 0x2d13 0x2d13 0x2c86 0x25c1 0x25d7 0x2bce 0x2d40 0x2d4f 0x2cac 0x25c1 0x25d7 0x2bea 0x2d5a 0x2da3 0x2cfc 0x25c1 0x25d4 0x2bfa 0x2d6f 0x2e1a 0x2da2 0x25c1 0x25d2 0x2c0c 0x2d78 0x2e4d 0x2def 0x25c1 0x25d2 0x2c2c 0x2d79 0x2ddd 0x2da7 0x25c0 0x25d2 0x2c48 0x2d7d 0x2d4e 0x2d36 0x25c0 0x25d2 0x2c4a 0x2d8c 0x2d42 0x2d0e 0x25c0 0x25d2 0x2c43 0x2dad 0x2d69 0x2cfe 0x25c0 0x25d2 0x2c29 0x2dc2 0x2d9a 0x2d09 0x25c0 0x25d1 0x2a43 0x2dc9 0x2ddf 0x2d37 0x25bf 0x25cf 0x27bd 0x2dd0 0x2e22 0x2d6f 0x25bf 0x25cd 0x271d 0x2de8 0x2e3b 0x2d8e 0x25bf 0x25cb 0x26f1 0x2e17 0x2e47 0x2dac 0x25bf 0x25c9 0x26ce 0x2e2b 0x2e56 0x2dbc 0x25bf 0x25c8 0x26a4 0x2e1e 0x2e75 0x2ddf 0x25be 0x25c6 0x2678 0x2e0a 0x2e8f 0x2e12 0x25be 0x25c5 0x2648 0x2dfb 0x2e89 0x2e1d 0x25be 0x25c4 0x2617 0x2df0 0x2e6d 0x2e00 0x25be 0x25c3 0x25ff 0x2de6 0x2e54 0x2de8 0x25be 0x25c2 0x25f5 0x2dda 0x2e39 0x2ddc 0x25be 0x25c1 0x25ee 0x2dca 0x2e17 0x2dcb 0x25be 0x25c0 0x25e6 0x2dae 0x2df4 0x2db7 0x25bd 0x25bf 0x25df 0x2d82 0x2dcd 0x2d94 0x25bd 0x25be 0x25d9 0x2d52 0x2db6 0x2d81 0x25bd 0x25be 0x25d4 0x2d18 0x2db9 0x2d7d 0x25bc 0x25bd 0x25cf 0x2cd7 0x2db7 0x2d73 0x25bc 0x25bd 0x25ca 0x2c8a 0x2d94 0x2d42 0x25bc 0x25bc 0x25c7 0x2ba8 0x2d6b 0x2cd3 0x25bb 0x25bc 0x25c6 0x2bc5 0x2d1d 0x2c6a 0x25bb 0x25bc 0x25c4 0x2ba8 0x2d65 0x2cae 0x25ba 0x25bb 0x25c3 0x2b9f 0x2d58 0x2caa 0x25b9 0x25bb 0x25c2 0x2baa 0x2d44 0x2cfa 0x25b8 0x25bb 0x25c0 0x2bb8 0x2d68 0x2cd6 0x25b7 0x25ba 0x25bf 0x2b5e 0x2d0c 0x2c24 0x25b6 0x25b9 0x25be 0x2ace 0x2cc9 0x2bd5 0x25b4 0x25b7 0x25bc 0x2a42 0x2c17 0x2b72 0x25b3 0x25b5 0x25ba 0x29d7 0x2bcd 0x2b33 0x25b3 0x25b5 0x25ba 0x29d7 0x2bcd 0x2b33 0x25b3 0x25b5 0x25ba 0x29d7 0x2bcd 0x2b33>;
	};

	qcom,pc-temp-y3-lut {
		qcom,lut-col-legend = <0xfffffff6 0x00 0x0a 0x19 0x28 0x32>;
		qcom,lut-row-legend = <0x2710 0x2648 0x2580 0x24b8 0x23f0 0x2328 0x2260 0x2198 0x20d0 0x2008 0x1f40 0x1e78 0x1db0 0x1ce8 0x1c20 0x1b58 0x1a90 0x19c8 0x1900 0x1838 0x1770 0x16a8 0x15e0 0x1518 0x1450 0x1388 0x12c0 0x11f8 0x1130 0x1068 0xfa0 0xed8 0xe10 0xd48 0xc80 0xbb8 0xaf0 0xa28 0x960 0x898 0x7d0 0x708 0x640 0x578 0x4b0 0x3e8 0x384 0x320 0x2bc 0x258 0x1f4 0x190 0x12c 0xc8 0x64 0x00>;
		qcom,lut-data = <0x3808 0x35f4 0x341e 0x33e5 0x33dc 0x33da 0x37a1 0x35c5 0x3425 0x33e8 0x33dd 0x33db 0x373d 0x3598 0x342d 0x33ec 0x33de 0x33dc 0x36e1 0x356e 0x3436 0x33f0 0x33e0 0x33dc 0x3691 0x3548 0x343c 0x33f3 0x33e1 0x33dd 0x3650 0x3529 0x343f 0x33f5 0x33e1 0x33de 0x3620 0x3511 0x343e 0x33f6 0x33e2 0x33df 0x35f6 0x34fb 0x343c 0x33f6 0x33e2 0x33df 0x35bd 0x34e0 0x343c 0x33f7 0x33e2 0x33df 0x3576 0x34bc 0x3440 0x33f7 0x33e2 0x33e0 0x3559 0x34a3 0x3442 0x33f7 0x33e2 0x33e0 0x3564 0x3498 0x3439 0x33f9 0x33e3 0x33e0 0x3571 0x3491 0x342d 0x33fb 0x33e5 0x33e0 0x355e 0x348a 0x342c 0x33fb 0x33e6 0x33e1 0x351d 0x347a 0x342d 0x33f8 0x33e6 0x33e3 0x34fe 0x346b 0x342e 0x33f7 0x33e7 0x33e4 0x34fd 0x3463 0x342c 0x33f8 0x33e8 0x33e4 0x34fc 0x345e 0x3428 0x33fa 0x33e9 0x33e4 0x34fc 0x3456 0x3424 0x33fa 0x33e9 0x33e4 0x34fe 0x344c 0x341e 0x33f8 0x33e8 0x33e4 0x34fe 0x3441 0x3419 0x33f6 0x33e7 0x33e3 0x34ff 0x3436 0x3414 0x33f2 0x33e4 0x33e0 0x34ff 0x342c 0x340f 0x33ee 0x33e0 0x33dc 0x3502 0x3426 0x340b 0x33ed 0x33df 0x33dc 0x350a 0x3422 0x3409 0x33ec 0x33df 0x33dc 0x3513 0x3421 0x3403 0x33ec 0x33df 0x33dc 0x351f 0x3425 0x33ec 0x33eb 0x33df 0x33dc 0x352d 0x342e 0x33d2 0x33eb 0x33df 0x33db 0x353a 0x3439 0x33ce 0x33eb 0x33df 0x33da 0x3549 0x344a 0x33cf 0x33eb 0x33df 0x33da 0x355a 0x345c 0x33d0 0x33ec 0x33df 0x33da 0x356e 0x346b 0x33d1 0x33ec 0x33e0 0x33db 0x3584 0x3479 0x33d4 0x33ed 0x33e1 0x33dc 0x359c 0x3489 0x33da 0x33ed 0x33e1 0x33dc 0x35b6 0x349b 0x33e7 0x33ed 0x33e1 0x33dc 0x35d1 0x34af 0x33ee 0x33ee 0x33e1 0x33dc 0x35eb 0x34c6 0x33f4 0x33ed 0x33df 0x33db 0x3608 0x34e1 0x33fb 0x33ec 0x33de 0x33da 0x362a 0x34fd 0x3403 0x33ec 0x33dd 0x33da 0x3651 0x351c 0x340c 0x33ed 0x33dd 0x33db 0x3679 0x353b 0x3418 0x33ee 0x33dd 0x33db 0x36a5 0x355a 0x3429 0x33ef 0x33dd 0x33dc 0x36d1 0x357c 0x343f 0x33ef 0x33de 0x33dc 0x36fc 0x35a5 0x345b 0x33f0 0x33de 0x33db 0x3719 0x35d5 0x3475 0x33ee 0x33df 0x33db 0x371e 0x35d6 0x347f 0x33f2 0x33e0 0x33de 0x3754 0x35e7 0x3495 0x33f3 0x33e5 0x33e3 0x37a3 0x3611 0x34ad 0x33f8 0x33e7 0x33e5 0x382a 0x363f 0x34c7 0x33fd 0x33eb 0x33e7 0x38ca 0x366a 0x34e7 0x3404 0x33ec 0x33e6 0x399c 0x3693 0x34fd 0x3401 0x33e6 0x33e1 0x3ad2 0x36e7 0x3525 0x3403 0x33e8 0x33e1 0x3ca8 0x37b2 0x3570 0x3408 0x33e9 0x33e4 0x3fa2 0x38f8 0x35ef 0x3414 0x33f0 0x33ea 0x3fa2 0x38f8 0x35ef 0x3414 0x33f0 0x33ea 0x3fa2 0x38f8 0x35ef 0x3414 0x33f0 0x33ea>;
	};

	qcom,pc-temp-y4-lut {
		qcom,lut-col-legend = <0xfffffff6 0x00 0x0a 0x19 0x28 0x32>;
		qcom,lut-row-legend = <0x2710 0x2648 0x2580 0x24b8 0x23f0 0x2328 0x2260 0x2198 0x20d0 0x2008 0x1f40 0x1e78 0x1db0 0x1ce8 0x1c20 0x1b58 0x1a90 0x19c8 0x1900 0x1838 0x1770 0x16a8 0x15e0 0x1518 0x1450 0x1388 0x12c0 0x11f8 0x1130 0x1068 0xfa0 0xed8 0xe10 0xd48 0xc80 0xbb8 0xaf0 0xa28 0x960 0x898 0x7d0 0x708 0x640 0x578 0x4b0 0x3e8 0x384 0x320 0x2bc 0x258 0x1f4 0x190 0x12c 0xc8 0x64 0x00>;
		qcom,lut-data = <0x41fa 0x418d 0x40c5 0x4068 0x4048 0x4040 0x4224 0x41aa 0x40db 0x406b 0x4046 0x4040 0x4250 0x41d3 0x40f5 0x406e 0x4045 0x403f 0x4278 0x41fc 0x410e 0x4071 0x4045 0x403f 0x4294 0x421c 0x4124 0x4074 0x4045 0x4040 0x429e 0x4229 0x4131 0x4076 0x4047 0x4040 0x4295 0x4225 0x4138 0x4078 0x4049 0x4042 0x4288 0x421d 0x413c 0x407b 0x404d 0x4044 0x4299 0x4226 0x413b 0x407e 0x4051 0x4046 0x42e1 0x425c 0x4134 0x4083 0x4056 0x404a 0x4306 0x428a 0x4130 0x408a 0x405a 0x404e 0x42f6 0x429a 0x4170 0x4092 0x405e 0x4052 0x42d5 0x42a4 0x41cd 0x409c 0x4061 0x4058 0x428f 0x4289 0x41c7 0x40a5 0x4066 0x405c 0x420b 0x41f2 0x4169 0x40ac 0x406e 0x4060 0x41cc 0x418d 0x4132 0x40b7 0x4077 0x4066 0x41c6 0x418a 0x4138 0x40d4 0x4085 0x4070 0x41c1 0x4189 0x4140 0x40f2 0x4095 0x407d 0x41b3 0x4183 0x413a 0x40f3 0x40a1 0x408a 0x419d 0x416b 0x4119 0x40e2 0x40ad 0x409a 0x418b 0x4150 0x40f5 0x40ca 0x40b0 0x409f 0x417e 0x4137 0x40d5 0x4099 0x4088 0x407d 0x4174 0x4122 0x40b8 0x4067 0x4052 0x4050 0x416d 0x411d 0x40a5 0x405c 0x4046 0x4044 0x4168 0x411b 0x4097 0x4059 0x4042 0x4040 0x4165 0x411a 0x4092 0x4058 0x4041 0x403f 0x4164 0x411a 0x40b1 0x405a 0x4045 0x4042 0x4164 0x411a 0x40da 0x405d 0x404b 0x4048 0x4164 0x4118 0x40e3 0x4061 0x4052 0x404f 0x4166 0x4113 0x40e5 0x4065 0x405b 0x4057 0x4168 0x4110 0x40e7 0x4068 0x4064 0x4060 0x416f 0x4111 0x40e7 0x406b 0x406e 0x406a 0x4176 0x4114 0x40e7 0x406e 0x4075 0x4073 0x417c 0x4118 0x40e5 0x406e 0x4075 0x4073 0x4181 0x411e 0x40e4 0x406f 0x4072 0x4070 0x4188 0x4123 0x40e5 0x406f 0x406c 0x406a 0x4193 0x4126 0x40eb 0x406d 0x405c 0x4059 0x41a1 0x4128 0x40f2 0x406a 0x404d 0x4049 0x41b2 0x4128 0x40f7 0x406a 0x404c 0x4048 0x41c6 0x4124 0x40fb 0x406b 0x404f 0x404b 0x41d8 0x4121 0x40fd 0x406e 0x4051 0x404d 0x41e8 0x4120 0x40fe 0x4074 0x4053 0x4050 0x41f7 0x4121 0x40fc 0x4078 0x4053 0x404f 0x4200 0x412a 0x40f2 0x4078 0x404b 0x4042 0x41e4 0x413d 0x40ee 0x407a 0x4045 0x403e 0x419d 0x4135 0x40e6 0x4078 0x4050 0x404b 0x41ab 0x413a 0x40ef 0x4085 0x405c 0x405c 0x41cd 0x4151 0x4103 0x409b 0x4070 0x4075 0x420a 0x416d 0x4122 0x40b6 0x408e 0x4090 0x423a 0x417e 0x414a 0x40d8 0x4096 0x4091 0x4282 0x4179 0x4156 0x40c1 0x405e 0x4051 0x4300 0x417c 0x412f 0x40a8 0x4055 0x404e 0x43d4 0x41c1 0x4129 0x40b3 0x405f 0x4051 0x45c7 0x4288 0x4164 0x40d0 0x4072 0x405b 0x45c7 0x4288 0x4164 0x40d0 0x4072 0x405b 0x45c7 0x4288 0x4164 0x40d0 0x4072 0x405b>;
	};

	qcom,pc-temp-y5-lut {
		qcom,lut-col-legend = <0xfffffff6 0x00 0x0a 0x19 0x28 0x32>;
		qcom,lut-row-legend = <0x2710 0x2648 0x2580 0x24b8 0x23f0 0x2328 0x2260 0x2198 0x20d0 0x2008 0x1f40 0x1e78 0x1db0 0x1ce8 0x1c20 0x1b58 0x1a90 0x19c8 0x1900 0x1838 0x1770 0x16a8 0x15e0 0x1518 0x1450 0x1388 0x12c0 0x11f8 0x1130 0x1068 0xfa0 0xed8 0xe10 0xd48 0xc80 0xbb8 0xaf0 0xa28 0x960 0x898 0x7d0 0x708 0x640 0x578 0x4b0 0x3e8 0x384 0x320 0x2bc 0x258 0x1f4 0x190 0x12c 0xc8 0x64 0x00>;
		qcom,lut-data = <0x2e7f 0x30b4 0x3399 0x3801 0x4e99 0x567b 0x2f77 0x3168 0x369d 0x3fd8 0x4f81 0x5831 0x3083 0x322e 0x3b70 0x46e5 0x4feb 0x5861 0x31a0 0x3303 0x40a5 0x4c9a 0x4fec 0x578e 0x32ce 0x33e6 0x44ca 0x5067 0x4f9a 0x563b 0x340c 0x34d6 0x466f 0x51ba 0x4f08 0x54ec 0x35b7 0x3618 0x461c 0x5074 0x4c21 0x529a 0x371e 0x373c 0x4593 0x4de4 0x476c 0x4f3b 0x36e0 0x370e 0x456f 0x4b32 0x43ff 0x4bf4 0x3547 0x3510 0x45b3 0x47cb 0x40fd 0x484f 0x34ca 0x33c9 0x45c4 0x4573 0x3f49 0x4516 0x457c 0x4053 0x443d 0x446e 0x3f7d 0x41f3 0x59a0 0x53f7 0x4257 0x4397 0x4068 0x3f7b 0x54ad 0x547a 0x4480 0x424f 0x406b 0x3f7b 0x3db2 0x426e 0x4edd 0x4066 0x3f15 0x4107 0x337e 0x368b 0x559d 0x3f7b 0x3e22 0x41e3 0x3436 0x3750 0x56f5 0x412e 0x3e25 0x4010 0x3532 0x389a 0x57e6 0x4502 0x3e29 0x3dd2 0x35c3 0x38e5 0x590b 0x4be7 0x4035 0x3eab 0x3636 0x38c1 0x5a81 0x58dd 0x496a 0x43c5 0x3644 0x3883 0x5b3a 0x5f1c 0x514b 0x49b2 0x34f8 0x37c6 0x5a45 0x5d4f 0x5551 0x5094 0x3374 0x3652 0x5897 0x5ade 0x5846 0x5712 0x32cf 0x3490 0x575d 0x5a22 0x59c7 0x59dd 0x325f 0x31fa 0x54ca 0x5a10 0x5a02 0x5b72 0x3245 0x30a0 0x5125 0x5971 0x58f5 0x5b50 0x3252 0x309d 0x43cd 0x5706 0x5527 0x54ca 0x325d 0x30a7 0x3441 0x54c4 0x5113 0x4c23 0x3258 0x30f0 0x31ba 0x557d 0x4feb 0x485c 0x3245 0x3220 0x3191 0x5991 0x4f78 0x4605 0x3223 0x3354 0x3176 0x5d8a 0x4fa0 0x4574 0x31c4 0x341e 0x31bd 0x6080 0x52c4 0x479c 0x3180 0x34c8 0x3270 0x62fa 0x57ca 0x4b67 0x31c2 0x354b 0x33ad 0x6470 0x5bfe 0x4ff1 0x3246 0x35af 0x35c9 0x6599 0x6013 0x5562 0x327d 0x361d 0x36d4 0x65de 0x6196 0x573e 0x328c 0x36ca 0x375b 0x622d 0x5e69 0x55f8 0x32a1 0x3784 0x37c0 0x5c47 0x58e7 0x5486 0x32d5 0x37ce 0x37a9 0x58df 0x54a7 0x5380 0x3334 0x37b7 0x3736 0x5697 0x50a7 0x5152 0x33ec 0x375a 0x36f4 0x56cd 0x4dc1 0x4fab 0x355a 0x35b8 0x36ed 0x540d 0x4bc3 0x4f2c 0x35f1 0x343c 0x3712 0x5043 0x4ba6 0x5013 0x3645 0x33f8 0x37fb 0x4d63 0x4da5 0x5343 0x3833 0x3460 0x36ba 0x4608 0x4eb7 0x4b15 0x3894 0x35c8 0x3664 0x4a2c 0x473c 0x476b 0x390a 0x364a 0x3800 0x465d 0x4d5f 0x4c5a 0x378f 0x36ee 0x386e 0x46e5 0x4b54 0x4ab2 0x3750 0x3826 0x37ef 0x47a3 0x4d20 0x4a36 0x3713 0x3ade 0x38b7 0x4c7c 0x4ea8 0x4886 0x33bc 0x3b44 0x382a 0x4b78 0x4f1a 0x480f 0x309d 0x37b8 0x3769 0x4d24 0x548a 0x4815 0x2c43 0x328e 0x37a3 0x498a 0x5189 0x4a26 0x28ac 0x2d77 0x33fc 0x4b56 0x5cee 0x59ca 0x28ac 0x2d77 0x33fc 0x4b56 0x5cee 0x59ca 0x28ac 0x2d77 0x33fc 0x4b56 0x5cee 0x59ca>;
	};

	qcom,pc-temp-y6-lut {
		qcom,lut-col-legend = <0xfffffff6 0x00 0x0a 0x19 0x28 0x32>;
		qcom,lut-row-legend = <0x2710 0x2648 0x2580 0x24b8 0x23f0 0x2328 0x2260 0x2198 0x20d0 0x2008 0x1f40 0x1e78 0x1db0 0x1ce8 0x1c20 0x1b58 0x1a90 0x19c8 0x1900 0x1838 0x1770 0x16a8 0x15e0 0x1518 0x1450 0x1388 0x12c0 0x11f8 0x1130 0x1068 0xfa0 0xed8 0xe10 0xd48 0xc80 0xbb8 0xaf0 0xa28 0x960 0x898 0x7d0 0x708 0x640 0x578 0x4b0 0x3e8 0x384 0x320 0x2bc 0x258 0x1f4 0x190 0x12c 0xc8 0x64 0x00>;
		qcom,lut-data = <0x1a7f 0x180a 0x156f 0x142c 0x13e4 0x13d9 0x1a3b 0x17e7 0x1575 0x142e 0x13e4 0x13d9 0x19fb 0x17c5 0x1578 0x1430 0x13e5 0x13d9 0x19be 0x17a5 0x1577 0x1432 0x13e5 0x13d9 0x1986 0x1787 0x1575 0x1433 0x13e6 0x13d9 0x1953 0x176b 0x1571 0x1433 0x13e6 0x13da 0x1924 0x1751 0x156b 0x1433 0x13e7 0x13db 0x18fa 0x173a 0x1563 0x1432 0x13e8 0x13db 0x18d8 0x1724 0x155c 0x1432 0x13e8 0x13dc 0x18bb 0x170d 0x1555 0x1433 0x13e9 0x13dd 0x18a7 0x1703 0x1552 0x1433 0x13eb 0x13df 0x189f 0x1705 0x1559 0x1436 0x13ec 0x13e0 0x1896 0x1709 0x1564 0x1439 0x13ee 0x13e1 0x1874 0x16fd 0x1560 0x143b 0x13f1 0x13e3 0x182b 0x16b9 0x1547 0x143c 0x13f3 0x13e6 0x1808 0x1688 0x1537 0x143d 0x13f6 0x13e9 0x1804 0x1684 0x1538 0x1445 0x13fa 0x13ec 0x1802 0x1681 0x1539 0x1450 0x13ff 0x13ef 0x17fd 0x167c 0x1536 0x1450 0x1403 0x13f3 0x17f7 0x1674 0x1529 0x144a 0x1405 0x13f7 0x17f3 0x166c 0x151b 0x1441 0x1406 0x13f8 0x17f1 0x1664 0x1510 0x1430 0x13f8 0x13ec 0x17ef 0x165e 0x1507 0x1420 0x13e6 0x13dc 0x17f0 0x165d 0x1504 0x141d 0x13e2 0x13d9 0x17f3 0x165e 0x1503 0x141c 0x13e2 0x13d8 0x17f7 0x1660 0x1502 0x141c 0x13e1 0x13d8 0x1800 0x1666 0x1504 0x141d 0x13e2 0x13d9 0x180b 0x1672 0x1508 0x141f 0x13e4 0x13da 0x1815 0x167e 0x150d 0x1422 0x13e7 0x13dc 0x1821 0x168d 0x1517 0x1425 0x13ea 0x13df 0x182f 0x169e 0x1522 0x1428 0x13ed 0x13e2 0x1841 0x16ae 0x152d 0x142b 0x13f1 0x13e6 0x1855 0x16be 0x153a 0x142d 0x13f4 0x13e9 0x1868 0x16cf 0x1549 0x1430 0x13f5 0x13ea 0x187c 0x16e3 0x155a 0x1432 0x13f4 0x13e9 0x1892 0x16f8 0x156c 0x1434 0x13f3 0x13e8 0x18ac 0x170f 0x157f 0x1435 0x13ef 0x13e3 0x18c8 0x1729 0x1592 0x1437 0x13ea 0x13de 0x18e8 0x1742 0x15a9 0x1439 0x13e9 0x13de 0x190b 0x175b 0x15c2 0x143e 0x13ea 0x13df 0x192e 0x1776 0x15dd 0x1444 0x13ec 0x13e0 0x1953 0x1793 0x15fa 0x144b 0x13ed 0x13e2 0x197c 0x17b4 0x161a 0x1452 0x13ee 0x13e2 0x19a5 0x17da 0x163c 0x145a 0x13ed 0x13df 0x19bf 0x1805 0x1661 0x1462 0x13ed 0x13de 0x19ba 0x180a 0x166c 0x1467 0x13f2 0x13e4 0x19eb 0x181b 0x1686 0x146f 0x13f9 0x13ed 0x1a45 0x1844 0x16a5 0x147f 0x1401 0x13f6 0x1ad8 0x1870 0x16c8 0x1490 0x140c 0x13ff 0x1b84 0x189b 0x16f1 0x14a3 0x140f 0x13ff 0x1c63 0x18bc 0x170f 0x149e 0x13fc 0x13e9 0x1db9 0x190f 0x172c 0x14a7 0x13fc 0x13e9 0x1f99 0x19f9 0x1775 0x14c4 0x1402 0x13ed 0x22c5 0x1b71 0x180c 0x14f3 0x1410 0x13f7 0x22c5 0x1b71 0x180c 0x14f3 0x1410 0x13f7 0x22c5 0x1b71 0x180c 0x14f3 0x1410 0x13f7>;
	};
};
